# HDSC_HC32F4A0 register map
Vendor: HDSC Co.,Ltd.; Series: ARMCM4; File version: 1.0
CPU: CM4 r0p1, little endian, MPU, FPU, 4 interrupt priority bits
Registers are 32-bit, read-write, reset 0x0 unless marked. A register's access mark holds for its fields unless they carry their own. Offsets are from the block's base; [hi:lo] are bit positions; {n}, {i} and the like mark numbered series.

## I2S1 — desc I2S
Base 0x4001E000
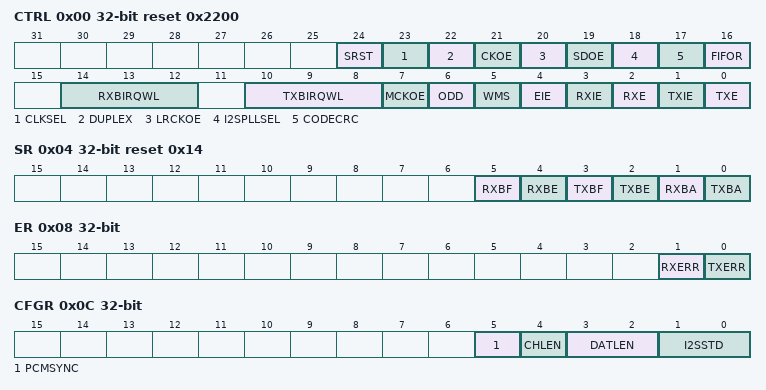
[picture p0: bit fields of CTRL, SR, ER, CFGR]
0x00 CTRL reset 0x2200
  [24] SRST, [23] CLKSEL, [22] DUPLEX, [21] CKOE, [20] LRCKOE, [19] SDOE, [18] I2SPLLSEL, [17] CODECRC, [16] FIFOR, [14:12] RXBIRQWL, [10:8] TXBIRQWL, [7] MCKOE, [6] ODD, [5] WMS, [4] EIE, [3] RXIE, [2] RXE, [1] TXIE, [0] TXE
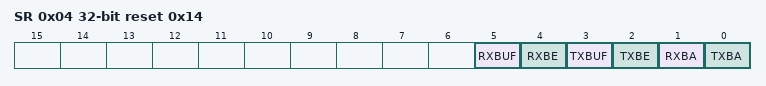
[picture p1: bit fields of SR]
0x04 SR ro reset 0x14
  [5] RXBF, [4] RXBE, [3] TXBF, [2] TXBE, [1] RXBA, [0] TXBA
0x08 ER
  [1] RXERR, [0] TXERR
0x0C CFGR
  [5] PCMSYNC, [4] CHLEN, [3:2] DATLEN, [1:0] I2SSTD
0x10 TXBUF wo
0x14 RXBUF ro
0x18 PR reset 0x2
  [7:0] I2SDIV

## I2S2
Base 0x4001E400
Same registers: I2S3 0x40022000, I2S4 0x40022400
Registers as I2S1; these are added or differ:
0x04 SR ro reset 0x14
  [5] RXBUF, [4] RXBE, [3] TXBUF, [2] TXBE, [1] RXBA, [0] TXBA

## ICG
Base 0x00000400
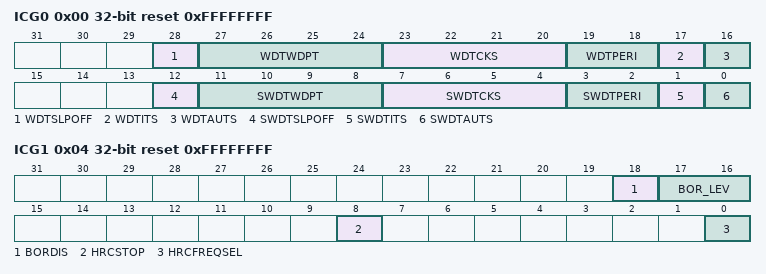
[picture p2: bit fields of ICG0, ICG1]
0x00 ICG0 ro reset 0xFFFFFFFF
  [28] WDTSLPOFF, [27:24] WDTWDPT, [23:20] WDTCKS, [19:18] WDTPERI, [17] WDTITS, [16] WDTAUTS, [12] SWDTSLPOFF, [11:8] SWDTWDPT, [7:4] SWDTCKS, [3:2] SWDTPERI, [1] SWDTITS, [0] SWDTAUTS
0x04 ICG1 ro reset 0xFFFFFFFF
  [18] BORDIS, [17:16] BOR_LEV, [8] HRCSTOP, [0] HRCFREQSEL
0x08 ICG2 ro reset 0xFFFFFFFF
  [23:0] BGO1M
0x0C ICG3 ro reset 0xFFFFFFFF
  [15:0] DBUSPRT

## INTC
Base 0x40051000
0x00 NOCCR
  [13:12] NOCSEL
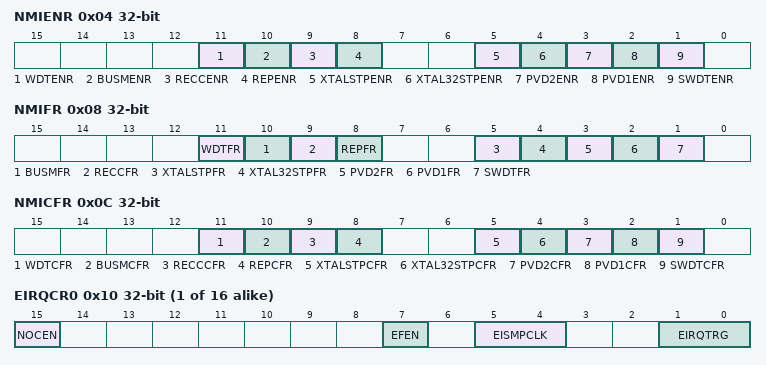
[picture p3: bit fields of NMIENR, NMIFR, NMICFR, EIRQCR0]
0x04 NMIENR
  [11] WDTENR, [10] BUSMENR, [9] RECCENR, [8] REPENR, [5] XTALSTPENR, [4] XTAL32STPENR, [3] PVD2ENR, [2] PVD1ENR, [1] SWDTENR
0x08 NMIFR
  [11] WDTFR, [10] BUSMFR, [9] RECCFR, [8] REPFR, [5] XTALSTPFR, [4] XTAL32STPFR, [3] PVD2FR, [2] PVD1FR, [1] SWDTFR
0x0C NMICFR
  [11] WDTCFR, [10] BUSMCFR, [9] RECCCFR, [8] REPCFR, [5] XTALSTPCFR, [4] XTAL32STPCFR, [3] PVD2CFR, [2] PVD1CFR, [1] SWDTCFR
{0x10+4i} EIRQCR{i} (i=0..15)
  [15] NOCEN, [7] EFEN, [5:4] EISMPCLK, [1:0] EIRQTRG
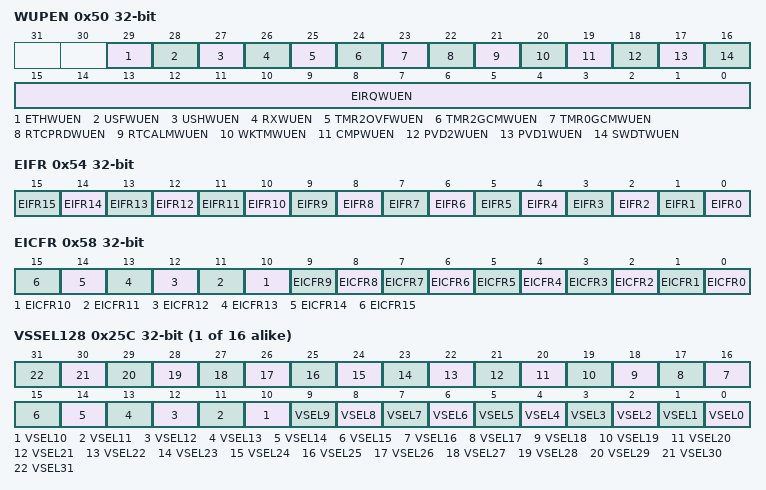
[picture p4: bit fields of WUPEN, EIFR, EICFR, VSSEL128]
0x50 WUPEN
  [29] ETHWUEN, [28] USFWUEN, [27] USHWUEN, [26] RXWUEN, [25] TMR2OVFWUEN, [24] TMR2GCMWUEN, [23] TMR0GCMWUEN, [22] RTCPRDWUEN, [21] RTCALMWUEN, [20] WKTMWUEN, [19] CMPWUEN, [18] PVD2WUEN, [17] PVD1WUEN, [16] SWDTWUEN, [15:0] EIRQWUEN
0x54 EIFR
  [n] EIFR{n} (n=0..15)
0x58 EICFR
  [n] EICFR{n} (n=0..15)
{0x5C+4i} SEL{i} reset 0x1FF (i=0..127)
  [8:0] INTSEL
{0x5C+4i} VSSEL{i} (i=128..143)
  [n] VSEL{n} (n=0..31)
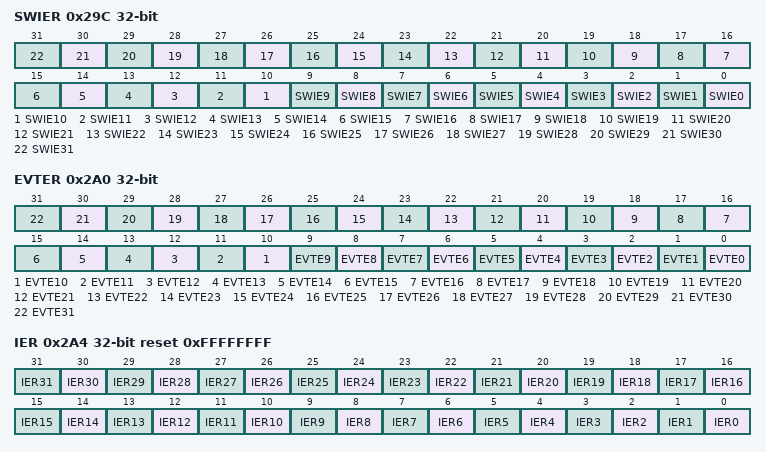
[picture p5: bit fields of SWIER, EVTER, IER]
0x29C SWIER
  [n] SWIE{n} (n=0..31)
0x2A0 EVTER
  [n] EVTE{n} (n=0..31)
0x2A4 IER reset 0xFFFFFFFF
  [n] IER{n} (n=0..31)

## KEYSCAN
Base 0x40050C00
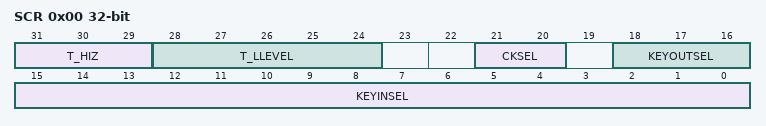
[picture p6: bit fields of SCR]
0x00 SCR
  [31:29] T_HIZ, [28:24] T_LLEVEL, [21:20] CKSEL, [18:16] KEYOUTSEL, [15:0] KEYINSEL
0x04 SER
  [0] SEN
0x08 SSR
  [2:0] INDEX

## MAU
Base 0x40055000
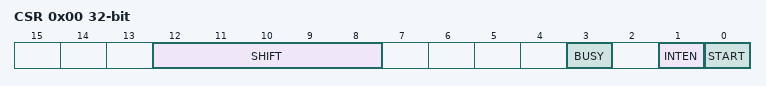
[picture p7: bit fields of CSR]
0x00 CSR
  [12:8] SHIFT, [3] BUSY, [1] INTEN, [0] START
0x04 DTR0
0x0C RTR0
  [16:0] SQRT_DOUT
0x10 DTR1
  [11:0] SIN_DIN
0x14 RTR1
  [15:0] SIN_DOUT

## MPU
Base 0x40050000; alternate view of ETH
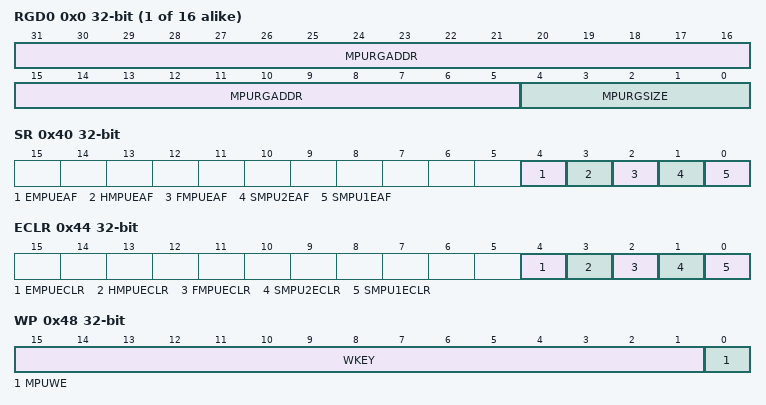
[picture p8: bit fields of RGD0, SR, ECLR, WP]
{0x0+4i} RGD{i} (i=0..15)
  [31:5] MPURGADDR, [4:0] MPURGSIZE
0x40 SR ro
  [4] EMPUEAF, [3] HMPUEAF, [2] FMPUEAF, [1] SMPU2EAF, [0] SMPU1EAF
0x44 ECLR wo
  [4] EMPUECLR, [3] HMPUECLR, [2] FMPUECLR, [1] SMPU2ECLR, [0] SMPU1ECLR
0x48 WP
  [15:1] WKEY wo, [0] MPUWE
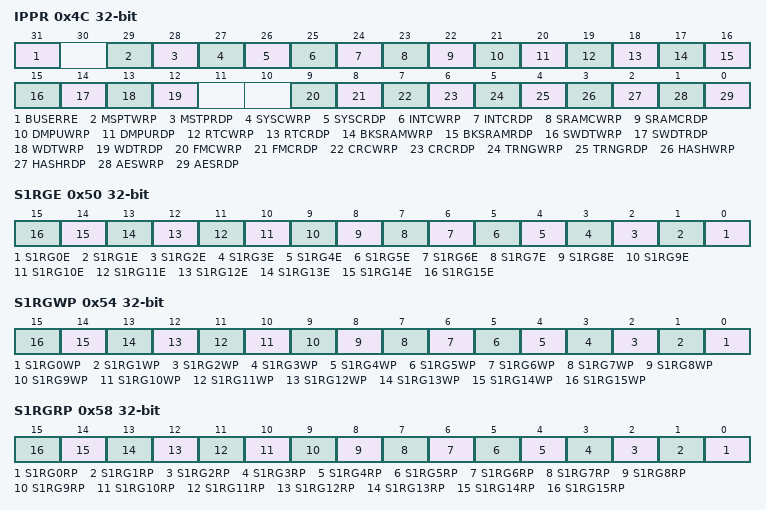
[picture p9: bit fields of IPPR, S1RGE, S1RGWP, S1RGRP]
0x4C IPPR
  [31] BUSERRE, [29] MSPTWRP, [28] MSTPRDP, [27] SYSCWRP, [26] SYSCRDP, [25] INTCWRP, [24] INTCRDP, [23] SRAMCWRP, [22] SRAMCRDP, [21] DMPUWRP, [20] DMPURDP, [19] RTCWRP, [18] RTCRDP, [17] BKSRAMWRP, [16] BKSRAMRDP, [15] SWDTWRP, [14] SWDTRDP, [13] WDTWRP, [12] WDTRDP, [9] FMCWRP, [8] FMCRDP, [7] CRCWRP, [6] CRCRDP, [5] TRNGWRP, [4] TRNGRDP, [3] HASHWRP, [2] HASHRDP, [1] AESWRP, [0] AESRDP
0x50 S1RGE
  [n] S1RG{n}E (n=0..15)
0x54 S1RGWP
  [n] S1RG{n}WP (n=0..15)
0x58 S1RGRP
  [n] S1RG{n}RP (n=0..15)
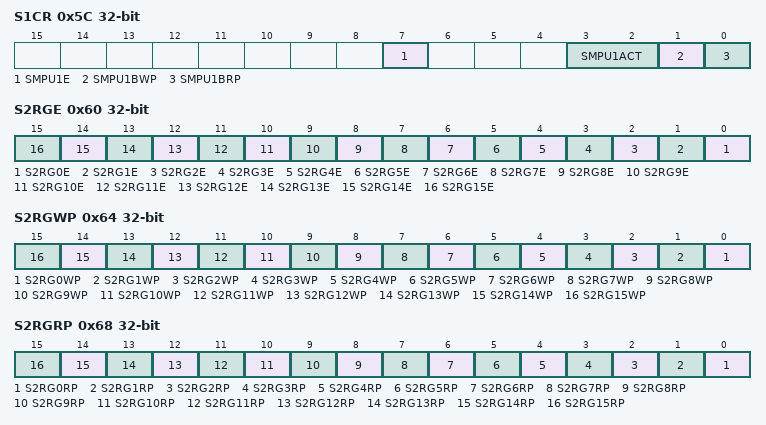
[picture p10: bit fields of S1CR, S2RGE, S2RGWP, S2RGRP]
0x5C S1CR
  [7] SMPU1E, [3:2] SMPU1ACT, [1] SMPU1BWP, [0] SMPU1BRP
0x60 S2RGE
  [n] S2RG{n}E (n=0..15)
0x64 S2RGWP
  [n] S2RG{n}WP (n=0..15)
0x68 S2RGRP
  [n] S2RG{n}RP (n=0..15)
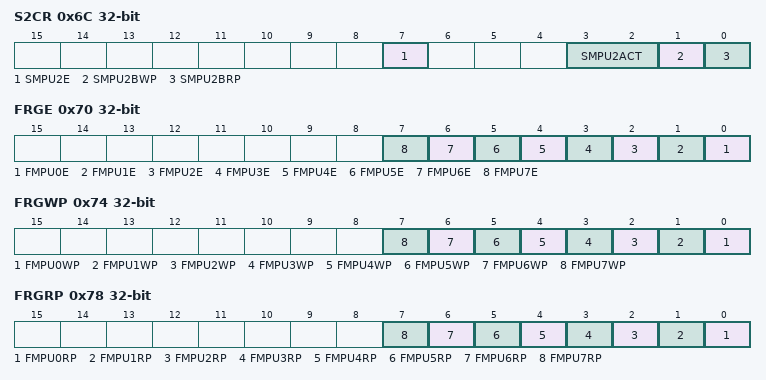
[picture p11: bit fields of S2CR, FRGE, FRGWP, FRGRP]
0x6C S2CR
  [7] SMPU2E, [3:2] SMPU2ACT, [1] SMPU2BWP, [0] SMPU2BRP
0x70 FRGE
  [n] FMPU{n}E (n=0..7)
0x74 FRGWP
  [n] FMPU{n}WP (n=0..7)
0x78 FRGRP
  [n] FMPU{n}RP (n=0..7)
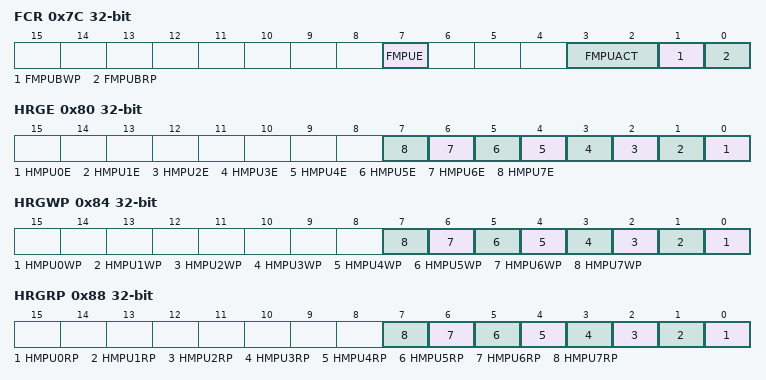
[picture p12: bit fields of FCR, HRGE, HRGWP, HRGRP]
0x7C FCR
  [7] FMPUE, [3:2] FMPUACT, [1] FMPUBWP, [0] FMPUBRP
0x80 HRGE
  [n] HMPU{n}E (n=0..7)
0x84 HRGWP
  [n] HMPU{n}WP (n=0..7)
0x88 HRGRP
  [n] HMPU{n}RP (n=0..7)
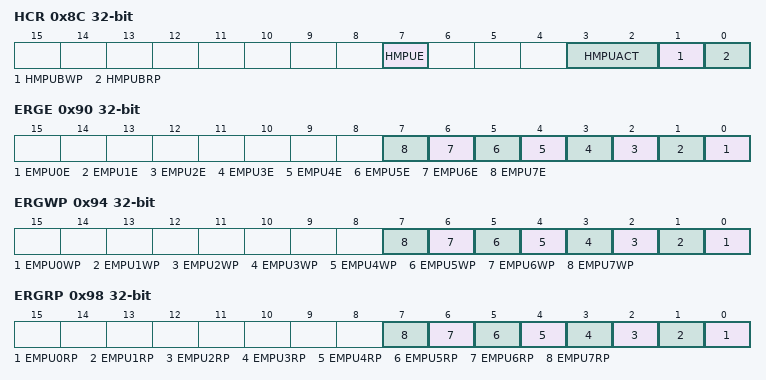
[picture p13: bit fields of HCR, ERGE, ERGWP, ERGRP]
0x8C HCR
  [7] HMPUE, [3:2] HMPUACT, [1] HMPUBWP, [0] HMPUBRP
0x90 ERGE
  [n] EMPU{n}E (n=0..7)
0x94 ERGWP
  [n] EMPU{n}WP (n=0..7)
0x98 ERGRP
  [n] EMPU{n}RP (n=0..7)
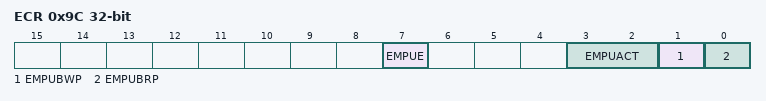
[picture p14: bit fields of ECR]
0x9C ECR
  [7] EMPUE, [3:2] EMPUACT, [1] EMPUBWP, [0] EMPUBRP
